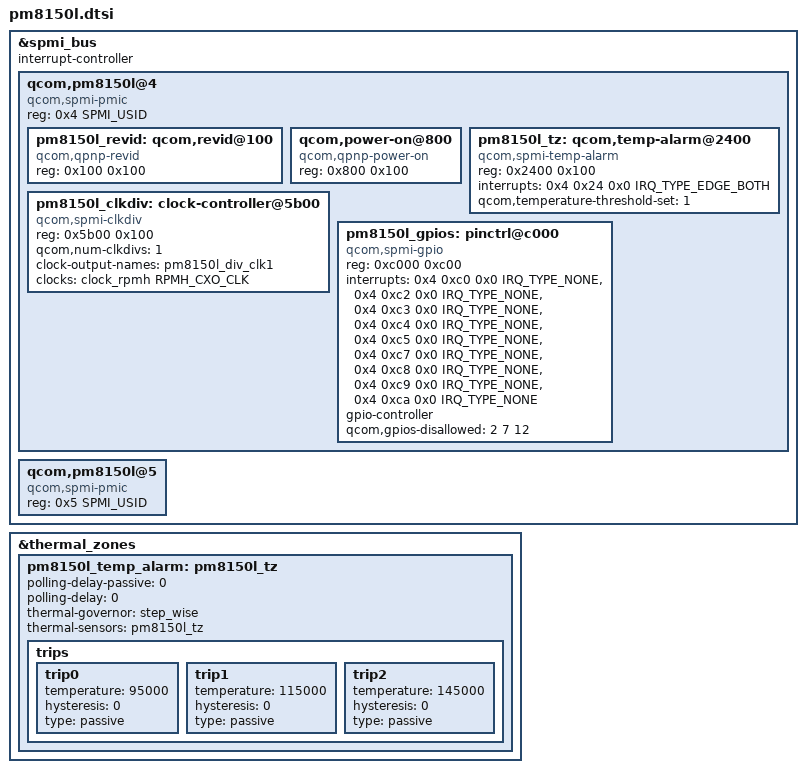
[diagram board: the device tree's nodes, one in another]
// SPDX-License-Identifier: GPL-2.0
/* Copyright (c) 2017-2018, The Linux Foundation. All rights reserved. */

#include <dt-bindings/spmi/spmi.h>
#include <dt-bindings/interrupt-controller/irq.h>

&spmi_bus {
	#address-cells = <2>;
	#size-cells = <0>;
	interrupt-controller;
	#interrupt-cells = <4>;

	qcom,pm8150l@4 {
		compatible = "qcom,spmi-pmic";
		reg = <0x4 SPMI_USID>;
		#address-cells = <2>;
		#size-cells = <0>;

		pm8150l_revid: qcom,revid@100 {
			compatible = "qcom,qpnp-revid";
			reg = <0x100 0x100>;
		};

		qcom,power-on@800 {
			compatible = "qcom,qpnp-power-on";
			reg = <0x800 0x100>;
		};

		pm8150l_tz: qcom,temp-alarm@2400 {
			compatible = "qcom,spmi-temp-alarm";
			reg = <0x2400 0x100>;
			interrupts = <0x4 0x24 0x0 IRQ_TYPE_EDGE_BOTH>;
			#thermal-sensor-cells = <0>;
			qcom,temperature-threshold-set = <1>;
		};

		pm8150l_clkdiv: clock-controller@5b00 {
			compatible = "qcom,spmi-clkdiv";
			reg = <0x5b00 0x100>;
			#clock-cells = <1>;
			qcom,num-clkdivs = <1>;
			clock-output-names = "pm8150l_div_clk1";
			clocks = <&clock_rpmh RPMH_CXO_CLK>;
			clock-names = "xo";
		};

		pm8150l_gpios: pinctrl@c000 {
			compatible = "qcom,spmi-gpio";
			reg = <0xc000 0xc00>;
			interrupts = <0x4 0xc0 0x0 IRQ_TYPE_NONE>,
					<0x4 0xc2 0x0 IRQ_TYPE_NONE>,
					<0x4 0xc3 0x0 IRQ_TYPE_NONE>,
					<0x4 0xc4 0x0 IRQ_TYPE_NONE>,
					<0x4 0xc5 0x0 IRQ_TYPE_NONE>,
					<0x4 0xc7 0x0 IRQ_TYPE_NONE>,
					<0x4 0xc8 0x0 IRQ_TYPE_NONE>,
					<0x4 0xc9 0x0 IRQ_TYPE_NONE>,
					<0x4 0xca 0x0 IRQ_TYPE_NONE>;
			interrupt-names = "pm8150l_gpio1", "pm8150l_gpio3",
					"pm8150l_gpio4", "pm8150l_gpio5",
					"pm8150l_gpio6", "pm8150l_gpio8",
					"pm8150l_gpio9", "pm8150l_gpio10",
					"pm8150l_gpio11";
			gpio-controller;
			#gpio-cells = <2>;
			qcom,gpios-disallowed = <2 7 12>;
		};
	};

	qcom,pm8150l@5 {
		compatible ="qcom,spmi-pmic";
		reg = <0x5 SPMI_USID>;
		#address-cells = <2>;
		#size-cells = <0>;
	};
};

&thermal_zones {
	pm8150l_temp_alarm: pm8150l_tz {
		polling-delay-passive = <0>;
		polling-delay = <0>;
		thermal-governor = "step_wise";
		thermal-sensors = <&pm8150l_tz>;

		trips {
			trip0 {
				temperature = <95000>;
				hysteresis = <0>;
				type = "passive";
			};

			trip1 {
				temperature = <115000>;
				hysteresis = <0>;
				type = "passive";
			};

			trip2 {
				temperature = <145000>;
				hysteresis = <0>;
				type = "passive";
			};
		};
	};
};
